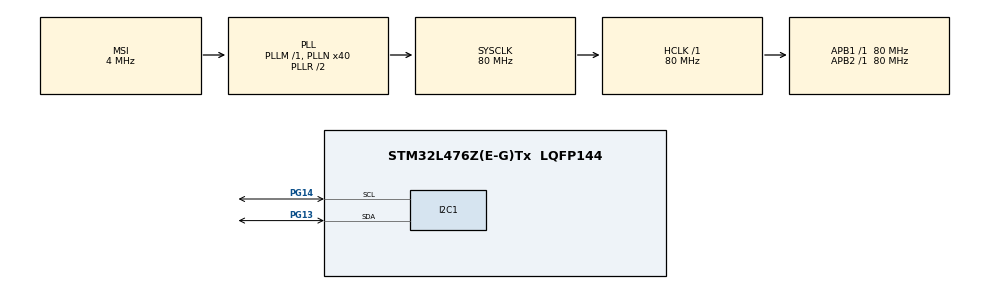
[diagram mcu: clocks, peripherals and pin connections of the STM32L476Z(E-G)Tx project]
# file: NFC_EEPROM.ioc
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I2C1.Timing=0x10909CEC
Mcu.Family=STM32L4
Mcu.Name=STM32L476Z(E-G)Tx
Mcu.Package=LQFP144
NVIC.PriorityGroup=NVIC_PRIORITYGROUP_4
PA13\ (JTMS-SWDIO).Mode=Serial_Wire
PA13\ (JTMS-SWDIO).Signal=SYS_JTMS-SWDIO
PA14\ (JTCK-SWCLK).Mode=Serial_Wire
PA14\ (JTCK-SWCLK).Signal=SYS_JTCK-SWCLK
PB10.Signal=I2C2_SCL
PB11.Signal=I2C2_SDA
PG13.Mode=I2C
PG13.Signal=I2C1_SDA
PG14.Mode=I2C
PG14.Signal=I2C1_SCL
PH0-OSC_IN\ (PH0).Mode=HSE-External-Oscillator
PH0-OSC_IN\ (PH0).Signal=RCC_OSC_IN
PH1-OSC_OUT\ (PH1).Mode=HSE-External-Oscillator
PH1-OSC_OUT\ (PH1).Signal=RCC_OSC_OUT
ProjectManager.HeapSize=0x200
ProjectManager.StackSize=0x400
ProjectManager.TargetToolchain=STM32CubeIDE
RCC.AHBFreq_Value=80000000
RCC.APB1Freq_Value=80000000
RCC.APB1TimFreq_Value=80000000
RCC.APB2Freq_Value=80000000
RCC.APB2TimFreq_Value=80000000
RCC.CortexFreq_Value=80000000
RCC.HCLKFreq_Value=80000000
RCC.HSE_VALUE=8000000
RCC.HSI_VALUE=16000000
RCC.LSE_VALUE=32768
RCC.MSI_VALUE=4000000
RCC.PLLN=40
RCC.SYSCLKFreq_VALUE=80000000
RCC.SYSCLKSource=RCC_SYSCLKSOURCE_PLLCLK
RCC.VCOOutputFreq_Value=160000000
board=custom

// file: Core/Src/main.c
/* USER CODE BEGIN Header */
/**
  ******************************************************************************
  * @file           : main.c
  * @brief          : Main program body
  ******************************************************************************
  * @attention
  *
  * Copyright (c) 2024 STMicroelectronics.
  * All rights reserved.
  *
  * This software is licensed under terms that can be found in the LICENSE file
  * in the root directory of this software component.
  * If no LICENSE file comes with this software, it is provided AS-IS.
  *
  ******************************************************************************
  */
/* USER CODE END Header */
#include "main.h"

/* USER CODE BEGIN Includes */
#include "string.h"
/* USER CODE END Includes */

I2C_HandleTypeDef hi2c1;

void SystemClock_Config(void);
static void MX_GPIO_Init(void);
static void MX_I2C1_Init(void);

/* USER CODE BEGIN 0 */
// Global Arrays(Buffer) to reading and writing data from EEPROM
uint8_t dataRead[20] ;
uint8_t dataWrite[50];
uint8_t dataW[] = "Zero Axis Technology ";

/* USER CODE END 0 */

int main(void)
{

  /* MCU Configuration--------------------------------------------------------*/

  /* Reset of all peripherals, Initializes the Flash interface and the Systick. */
  HAL_Init();

  /* Configure the system clock */
  SystemClock_Config();

  /* Initialize all configured peripherals */
  MX_GPIO_Init();
  MX_I2C1_Init();
  /* USER CODE BEGIN 2 */

  //erasing entire ROM
//  for(int i = 0; i< 256; i++)
//  {
//	  EEPROM_PageErase(i);
//
//  }
//  for(int i = 0; i < 100; i++)
//  {
//	  dataWrite[i] = i+10;
//  }

//  HAL_I2C_Mem_Write(&hi2c1, I2C_ADDRESS, (1<<6), 2, dataWrite, 70, 1000);
//  HAL_Delay(5);
////
////
//HAL_I2C_Mem_Read(&hi2c1, I2C_ADDRESS, (1<<6), 2, dataRead, 64, 1000);
////
  EEPROM_Write(1,dataW, strlen((char *)dataW));
  EEPROM_Read(1,dataRead, 8);

  /* USER CODE END 2 */

  /* Infinite loop */
  /* USER CODE BEGIN WHILE */
  while (1)
  {
	  if (HAL_I2C_IsDeviceReady(&hi2c1, I2C_ADDRESS, 1, 100)!= HAL_OK)
	 {
	 	printf("error");
	 }

    /* USER CODE END WHILE */

  }
}

void SystemClock_Config(void)
{
  RCC_OscInitTypeDef RCC_OscInitStruct = {0};
  RCC_ClkInitTypeDef RCC_ClkInitStruct = {0};

  /** Configure the main internal regulator output voltage
  */
  if (HAL_PWREx_ControlVoltageScaling(PWR_REGULATOR_VOLTAGE_SCALE1) != HAL_OK)
  {
    Error_Handler();
  }

  /** Initializes the RCC Oscillators according to the specified parameters
  * in the RCC_OscInitTypeDef structure.
  */
  RCC_OscInitStruct.OscillatorType = RCC_OSCILLATORTYPE_MSI;
  RCC_OscInitStruct.MSIState = RCC_MSI_ON;
  RCC_OscInitStruct.MSICalibrationValue = 0;
  RCC_OscInitStruct.MSIClockRange = RCC_MSIRANGE_6;
  RCC_OscInitStruct.PLL.PLLState = RCC_PLL_ON;
  RCC_OscInitStruct.PLL.PLLSource = RCC_PLLSOURCE_MSI;
  RCC_OscInitStruct.PLL.PLLM = 1;
  RCC_OscInitStruct.PLL.PLLN = 40;
  RCC_OscInitStruct.PLL.PLLP = RCC_PLLP_DIV7;
  RCC_OscInitStruct.PLL.PLLQ = RCC_PLLQ_DIV2;
  RCC_OscInitStruct.PLL.PLLR = RCC_PLLR_DIV2;
  if (HAL_RCC_OscConfig(&RCC_OscInitStruct) != HAL_OK)
  {
    Error_Handler();
  }

  /** Initializes the CPU, AHB and APB buses clocks
  */
  RCC_ClkInitStruct.ClockType = RCC_CLOCKTYPE_HCLK|RCC_CLOCKTYPE_SYSCLK
                              |RCC_CLOCKTYPE_PCLK1|RCC_CLOCKTYPE_PCLK2;
  RCC_ClkInitStruct.SYSCLKSource = RCC_SYSCLKSOURCE_PLLCLK;
  RCC_ClkInitStruct.AHBCLKDivider = RCC_SYSCLK_DIV1;
  RCC_ClkInitStruct.APB1CLKDivider = RCC_HCLK_DIV1;
  RCC_ClkInitStruct.APB2CLKDivider = RCC_HCLK_DIV1;

  if (HAL_RCC_ClockConfig(&RCC_ClkInitStruct, FLASH_LATENCY_4) != HAL_OK)
  {
    Error_Handler();
  }
}

static void MX_I2C1_Init(void)
{

  hi2c1.Instance = I2C1;
  hi2c1.Init.Timing = 0x10909CEC;
  hi2c1.Init.OwnAddress1 = 0;
  hi2c1.Init.AddressingMode = I2C_ADDRESSINGMODE_7BIT;
  hi2c1.Init.DualAddressMode = I2C_DUALADDRESS_DISABLE;
  hi2c1.Init.OwnAddress2 = 0;
  hi2c1.Init.OwnAddress2Masks = I2C_OA2_NOMASK;
  hi2c1.Init.GeneralCallMode = I2C_GENERALCALL_DISABLE;
  hi2c1.Init.NoStretchMode = I2C_NOSTRETCH_DISABLE;
  if (HAL_I2C_Init(&hi2c1) != HAL_OK)
  {
    Error_Handler();
  }

  /** Configure Analogue filter
  */
  if (HAL_I2CEx_ConfigAnalogFilter(&hi2c1, I2C_ANALOGFILTER_ENABLE) != HAL_OK)
  {
    Error_Handler();
  }

  /** Configure Digital filter
  */
  if (HAL_I2CEx_ConfigDigitalFilter(&hi2c1, 0) != HAL_OK)
  {
    Error_Handler();
  }

}

static void MX_GPIO_Init(void)
{
  GPIO_InitTypeDef GPIO_InitStruct = {0};

  /* GPIO Ports Clock Enable */
  __HAL_RCC_GPIOH_CLK_ENABLE();
  __HAL_RCC_GPIOB_CLK_ENABLE();
  __HAL_RCC_GPIOA_CLK_ENABLE();
  __HAL_RCC_GPIOG_CLK_ENABLE();
  HAL_PWREx_EnableVddIO2();

  /*Configure GPIO pins : PB10 PB11 */
  GPIO_InitStruct.Pin = GPIO_PIN_10|GPIO_PIN_11;
  GPIO_InitStruct.Mode = GPIO_MODE_AF_OD;
  GPIO_InitStruct.Pull = GPIO_NOPULL;
  GPIO_InitStruct.Speed = GPIO_SPEED_FREQ_VERY_HIGH;
  GPIO_InitStruct.Alternate = GPIO_AF4_I2C2;
  HAL_GPIO_Init(GPIOB, &GPIO_InitStruct);

}

void Error_Handler(void)
{
  __disable_irq();
  while (1)
  {
  }
}
